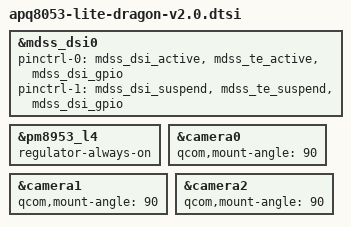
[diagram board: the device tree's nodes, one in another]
/*
 * Copyright (c) 2017-2018, The Linux Foundation. All rights reserved.
 *
 * This program is free software; you can redistribute it and/or modify
 * it under the terms of the GNU General Public License version 2 and
 * only version 2 as published by the Free Software Foundation.
 *
 * This program is distributed in the hope that it will be useful,
 * but WITHOUT ANY WARRANTY; without even the implied warranty of
 * MERCHANTABILITY or FITNESS FOR A PARTICULAR PURPOSE.  See the
 * GNU General Public License for more details.
 */

#include "apq8053-lite-dragon.dtsi"

&mdss_dsi0 {
	pinctrl-0 = <&mdss_dsi_active &mdss_te_active &mdss_dsi_gpio>;
	pinctrl-1 = <&mdss_dsi_suspend &mdss_te_suspend &mdss_dsi_gpio>;
};

&pm8953_l4 {
	status = "okay";
	regulator-always-on;
};

&camera0 {
	qcom,mount-angle = <90>;
};

&camera1 {
	qcom,mount-angle = <90>;
};

&camera2{
	qcom,mount-angle = <90>;
};
